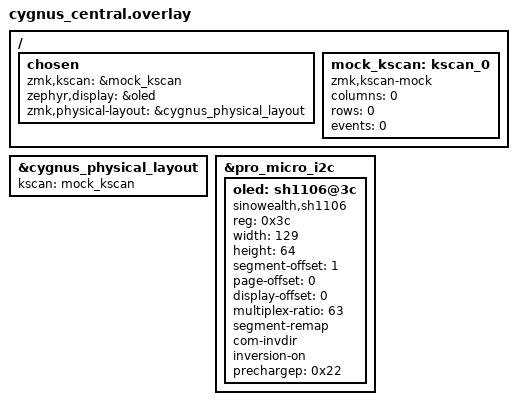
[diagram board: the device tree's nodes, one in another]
#include <dt-bindings/zmk/matrix_transform.h>
#include "cygnus.dtsi"

/ {
    chosen {
        zmk,kscan = &mock_kscan;
        zephyr,display = &oled;
        zmk,physical-layout = &cygnus_physical_layout;
    };

    mock_kscan: kscan_0 {
        compatible = "zmk,kscan-mock";
        columns = <0>;
        rows = <0>;
        events = <0>;
    };
};

&cygnus_physical_layout {
        kscan = <&mock_kscan>;
};

&pro_micro_i2c {
    status = "okay";
     oled: sh1106@3c {
        compatible = "sinowealth,sh1106";
        reg = <0x3c>;
        width = <129>;
        height = <64>;
        segment-offset = <1>;
        page-offset = <0>;
        display-offset = <0>;
        multiplex-ratio = <63>;
        segment-remap;
        com-invdir;
        inversion-on;
        prechargep = <0x22>;
        };
}; 
